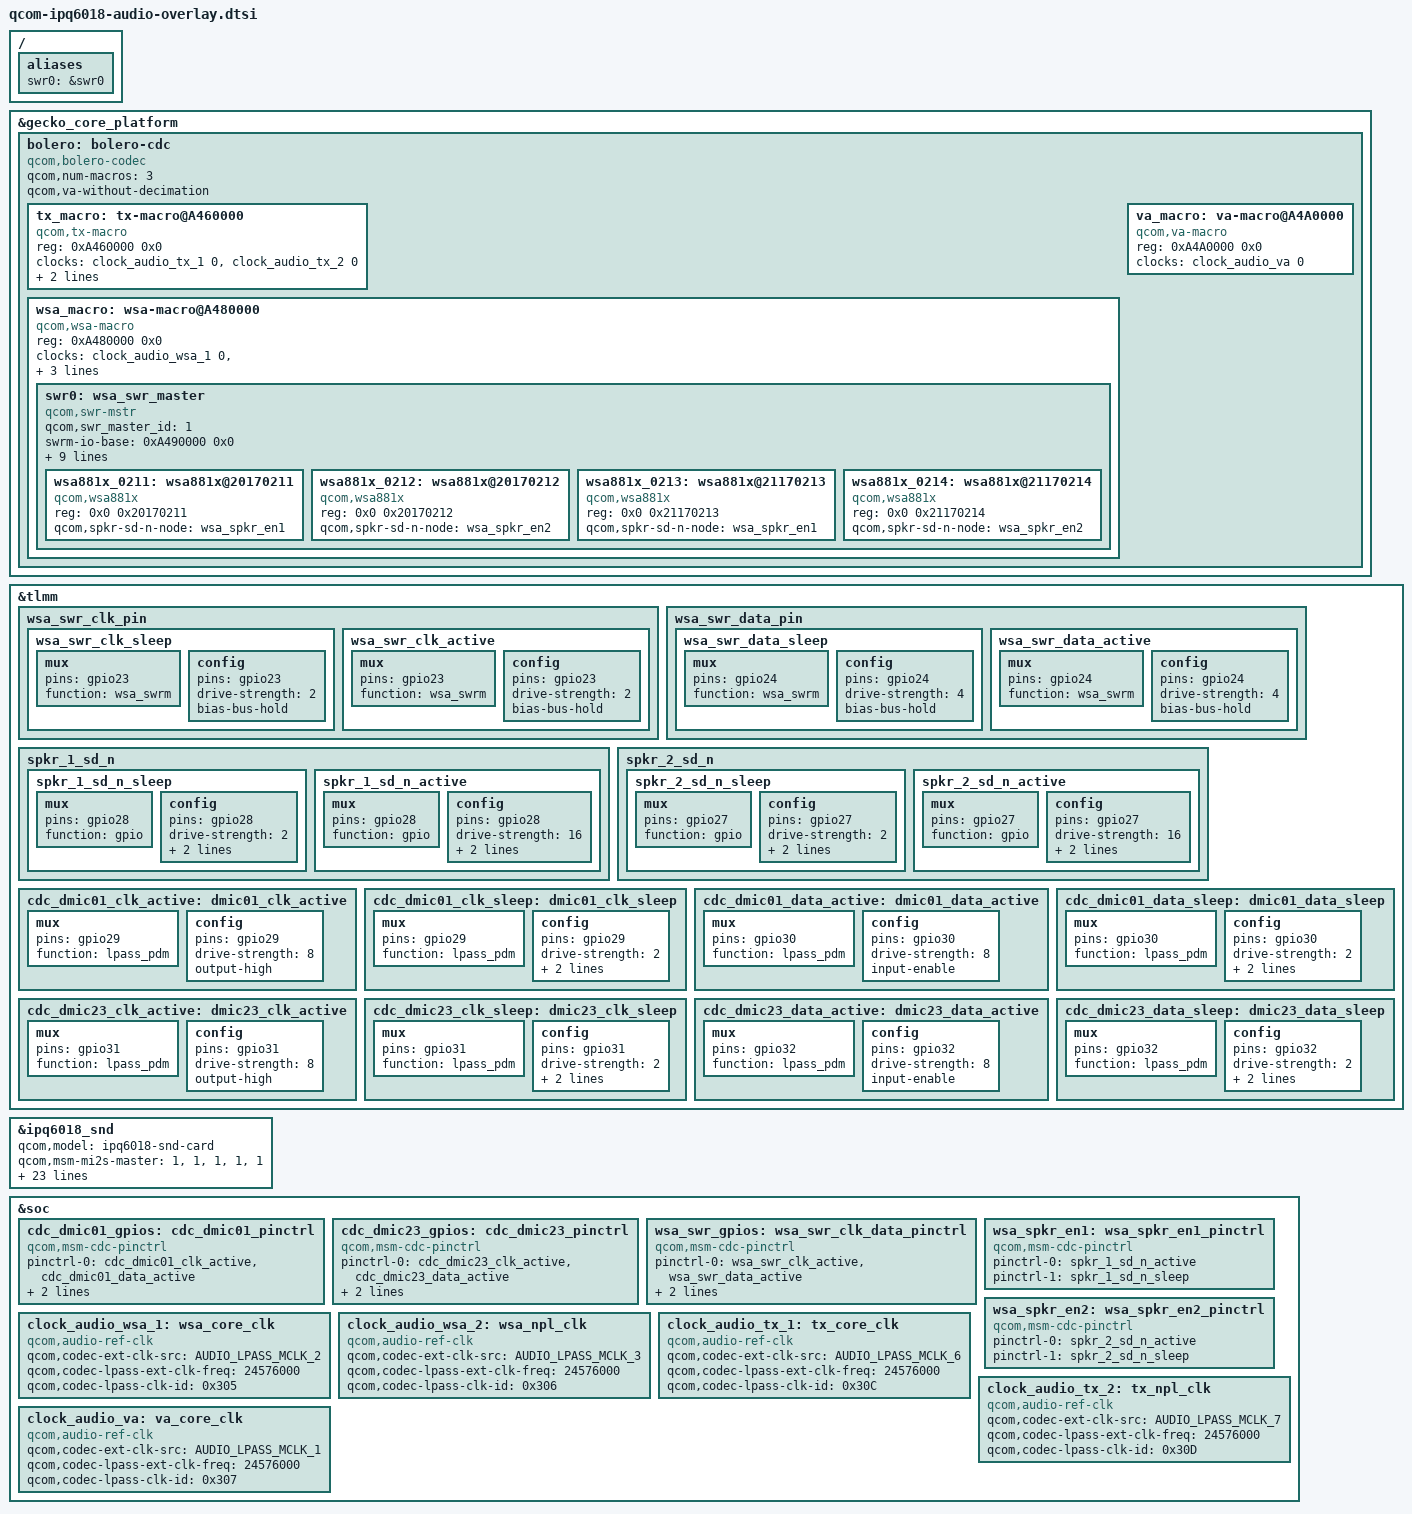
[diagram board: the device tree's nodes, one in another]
/*
 * Copyright (c) 2019, The Linux Foundation. All rights reserved.
 *
 * This program is free software; you can redistribute it and/or modify
 * it under the terms of the GNU General Public License version 2 and
 * only version 2 as published by the Free Software Foundation.
 *
 * This program is distributed in the hope that it will be useful,
 * but WITHOUT ANY WARRANTY; without even the implied warranty of
 * MERCHANTABILITY or FITNESS FOR A PARTICULAR PURPOSE.  See the
 * GNU General Public License for more details.
 */

#include <dt-bindings/clock/qcom,audio-ext-clk.h>
#include <dt-bindings/sound/audio-codec-port-types.h>
#include "qcom-ipq6018-audio.dtsi"

/ {
	aliases {
		swr0 = &swr0;
	};
};

&gecko_core_platform {
	bolero: bolero-cdc {
		compatible = "qcom,bolero-codec";
		tx_macro: tx-macro@A460000 {
		};

		wsa_macro: wsa-macro@A480000 {
			swr0: wsa_swr_master {
			};
		};
	};
};

&bolero {
	qcom,num-macros = <3>;
	qcom,va-without-decimation;
	#address-cells = <1>;
	#size-cells = <1>;
	tx_macro: tx-macro@A460000 {
		compatible = "qcom,tx-macro";
		reg = <0xA460000 0x0>;
		clock-names = "tx_core_clk", "tx_npl_clk";
		clocks = <&clock_audio_tx_1 0>,
			 <&clock_audio_tx_2 0>;
		qcom,tx-dmic-sample-rate = <3072000>;
		qcom,tx-mclk-freq = <12288000>;
	};

	wsa_macro: wsa-macro@A480000 {
		compatible = "qcom,wsa-macro";
		reg = <0xA480000 0x0>;
		clock-names = "wsa_core_clk", "wsa_npl_clk";
		clocks = <&clock_audio_wsa_1 0>,
			 <&clock_audio_wsa_2 0>;
		qcom,wsa-mclk-freq = <12288000>;
		qcom,wsa-swr-gpios = <&wsa_swr_gpios>;
		swr0: wsa_swr_master {
			compatible = "qcom,swr-mstr";
			#address-cells = <2>;
			#size-cells = <0>;
			qcom,swr_master_id = <1>;
			swrm-io-base = <0xA490000 0x0>;
			interrupts = <0 141 0>;
			interrupt-names = "swr_master_irq";
			qcom,swr-num-ports = <8>;
			qcom,swr-port-mapping = <1 SPKR_L 0x1>,
				<2 SPKR_L_COMP 0xF>, <3 SPKR_L_BOOST 0x3>,
				<4 SPKR_R 0x1>, <5 SPKR_R_COMP 0xF>,
				<6 SPKR_R_BOOST 0x3>, <7 SPKR_L_VI 0x3>,
				<8 SPKR_R_VI 0x3>;
			qcom,swr-num-dev = <2>;
			qcom,swr-mclk-freq = <12288000>;
			wsa881x_0211: wsa881x@20170211 {
				compatible = "qcom,wsa881x";
				reg = <0x0 0x20170211>;
				qcom,spkr-sd-n-node = <&wsa_spkr_en1>;
			};

			wsa881x_0212: wsa881x@20170212 {
				compatible = "qcom,wsa881x";
				reg = <0x0 0x20170212>;
				qcom,spkr-sd-n-node = <&wsa_spkr_en2>;
			};

			wsa881x_0213: wsa881x@21170213 {
				compatible = "qcom,wsa881x";
				reg = <0x0 0x21170213>;
				qcom,spkr-sd-n-node = <&wsa_spkr_en1>;
			};

			wsa881x_0214: wsa881x@21170214 {
				compatible = "qcom,wsa881x";
				reg = <0x0 0x21170214>;
				qcom,spkr-sd-n-node = <&wsa_spkr_en2>;
			};
		};

	};

	va_macro: va-macro@A4A0000 {
		compatible = "qcom,va-macro";
		reg = <0xA4A0000 0x0>;
		clock-names = "va_core_clk";
		clocks = <&clock_audio_va 0>;
	};

};

&tlmm {
	wsa_swr_clk_pin {
		wsa_swr_clk_sleep: wsa_swr_clk_sleep {
			mux {
				pins = "gpio23";
				function = "wsa_swrm";
			};

			config {
				pins = "gpio23";
				drive-strength = <2>;
				bias-bus-hold;
			};
		};

		wsa_swr_clk_active: wsa_swr_clk_active {
			mux {
				pins = "gpio23";
				function = "wsa_swrm";
			};

			config {
				pins = "gpio23";
				drive-strength = <2>;
				bias-bus-hold;
			};
		};
	};

	wsa_swr_data_pin {
		wsa_swr_data_sleep: wsa_swr_data_sleep {
			mux {
				pins = "gpio24";
				function = "wsa_swrm";
			};

			config {
				pins = "gpio24";
				drive-strength = <4>;
				bias-bus-hold;
			};
		};

		wsa_swr_data_active: wsa_swr_data_active {
			mux {
				pins = "gpio24";
				function = "wsa_swrm";
			};

			config {
				pins = "gpio24";
				drive-strength = <4>;
				bias-bus-hold;
			};
		};
	};

	/* WSA speaker reset pins */
	spkr_1_sd_n {
		spkr_1_sd_n_sleep: spkr_1_sd_n_sleep {
			mux {
				pins = "gpio28";
				function = "gpio";
			};

			config {
				pins = "gpio28";
				drive-strength = <2>;
				bias-pull-down;
				input-enable;
			};
		};

		spkr_1_sd_n_active: spkr_1_sd_n_active {
			mux {
				pins = "gpio28";
				function = "gpio";
			};

			config {
				pins = "gpio28";
				drive-strength = <16>;
				bias-disable;
				output-high;
			};
		};
	};

	spkr_2_sd_n {
		spkr_2_sd_n_sleep: spkr_2_sd_n_sleep {
			mux {
				pins = "gpio27";
				function = "gpio";
			};

			config {
				pins = "gpio27";
				drive-strength = <2>;
				bias-pull-down;
				input-enable;
			};
		};

		spkr_2_sd_n_active: spkr_2_sd_n_active {
			mux {
				pins = "gpio27";
				function = "gpio";
			};

			config {
				pins = "gpio27";
				drive-strength = <16>;
				bias-disable;
				output-high;
			};
		};
	};

	cdc_dmic01_clk_active: dmic01_clk_active {
		mux {
			pins = "gpio29";
			function = "lpass_pdm";
		};

		config {
			pins = "gpio29";
			drive-strength = <8>;
			output-high;
		};
	};

	cdc_dmic01_clk_sleep: dmic01_clk_sleep {
		mux {
			pins = "gpio29";
			function = "lpass_pdm";
		};

		config {
			pins = "gpio29";
			drive-strength = <2>;
			bias-disable;
			output-low;
		};
	};

	cdc_dmic01_data_active: dmic01_data_active {
		mux {
			pins = "gpio30";
			function = "lpass_pdm";
		};

		config {
			pins = "gpio30";
			drive-strength = <8>;
			input-enable;
		};
	};

	cdc_dmic01_data_sleep: dmic01_data_sleep {
		mux {
			pins = "gpio30";
			function = "lpass_pdm";
		};

		config {
			pins = "gpio30";
			drive-strength = <2>;
			pull-down;
			input-enable;
		};
	};

	cdc_dmic23_clk_active: dmic23_clk_active {
		mux {
			pins = "gpio31";
			function = "lpass_pdm";
		};

		config {
			pins = "gpio31";
			drive-strength = <8>;
			output-high;
		};
	};

	cdc_dmic23_clk_sleep: dmic23_clk_sleep {
		mux {
			pins = "gpio31";
			function = "lpass_pdm";
		};

		config {
			pins = "gpio31";
			drive-strength = <2>;
			bias-disable;
			output-low;
		};
	};

	cdc_dmic23_data_active: dmic23_data_active {
		mux {
			pins = "gpio32";
			function = "lpass_pdm";
		};

		config {
			pins = "gpio32";
			drive-strength = <8>;
			input-enable;
		};
	};

	cdc_dmic23_data_sleep: dmic23_data_sleep {
		mux {
			pins = "gpio32";
			function = "lpass_pdm";
		};

		config {
			pins = "gpio32";
			drive-strength = <2>;
			pull-down;
			input-enable;
		};
	};
};

&ipq6018_snd {
	qcom,model = "ipq6018-snd-card";
	qcom,msm-mi2s-master = <1>, <1>, <1>, <1>, <1>;
	qcom,audio-routing =
		"TX_AIF1 CAP", "VA_MCLK",
		"TX DMIC0", "TX MIC BIAS1",
		"TX MIC BIAS1", "Digital Mic0",
		"TX DMIC1", "TX MIC BIAS1",
		"TX MIC BIAS1", "Digital Mic1",
		"TX DMIC2", "TX MIC BIAS1",
		"TX MIC BIAS1", "Digital Mic2",
		"TX DMIC3", "TX MIC BIAS1",
		"TX MIC BIAS1", "Digital Mic3",
		"TX_AIF2 CAP", "VA_MCLK",
		"WSA_TX DEC0_INP", "TX DEC0 MUX",
		"WSA_TX DEC1_INP", "TX DEC1 MUX",
		"SpkrLeft IN", "WSA_SPK1 OUT",
		"SpkrRight IN", "WSA_SPK2 OUT",
		"WSA_SPK1 OUT", "VA_MCLK",
		"WSA_SPK2 OUT", "VA_MCLK";
	qcom,cdc-dmic01-gpios = <&cdc_dmic01_gpios>;
	qcom,cdc-dmic23-gpios = <&cdc_dmic23_gpios>;
	asoc-codec  = <&stub_codec>, <&bolero>;
	asoc-codec-names = "msm-stub-codec.1", "bolero_codec";
	qcom,wsa-max-devs = <2>;
	qcom,wsa-devs = <&wsa881x_0211>, <&wsa881x_0212>,
			<&wsa881x_0213>, <&wsa881x_0214>;
	qcom,wsa-aux-dev-prefix = "SpkrLeft", "SpkrRight",
				  "SpkrLeft", "SpkrRight";
	qcom,msm_audio_ssr_devs = <&gecko_core_platform>,
					<&bolero>;
};

&soc {
	cdc_dmic01_gpios: cdc_dmic01_pinctrl {
		compatible = "qcom,msm-cdc-pinctrl";
		pinctrl-names = "aud_active", "aud_sleep";
		pinctrl-0 = <&cdc_dmic01_clk_active &cdc_dmic01_data_active>;
		pinctrl-1 = <&cdc_dmic01_clk_sleep &cdc_dmic01_data_sleep>;
	};

	cdc_dmic23_gpios: cdc_dmic23_pinctrl {
		compatible = "qcom,msm-cdc-pinctrl";
		pinctrl-names = "aud_active", "aud_sleep";
		pinctrl-0 = <&cdc_dmic23_clk_active &cdc_dmic23_data_active>;
		pinctrl-1 = <&cdc_dmic23_clk_sleep &cdc_dmic23_data_sleep>;
	};

	wsa_swr_gpios: wsa_swr_clk_data_pinctrl {
		compatible = "qcom,msm-cdc-pinctrl";
		pinctrl-names = "aud_active", "aud_sleep";
		pinctrl-0 = <&wsa_swr_clk_active &wsa_swr_data_active>;
		pinctrl-1 = <&wsa_swr_clk_sleep &wsa_swr_data_sleep>;
	};

	wsa_spkr_en1: wsa_spkr_en1_pinctrl {
		compatible = "qcom,msm-cdc-pinctrl";
		pinctrl-names = "aud_active", "aud_sleep";
		pinctrl-0 = <&spkr_1_sd_n_active>;
		pinctrl-1 = <&spkr_1_sd_n_sleep>;
	};

	wsa_spkr_en2: wsa_spkr_en2_pinctrl {
		compatible = "qcom,msm-cdc-pinctrl";
		pinctrl-names = "aud_active", "aud_sleep";
		pinctrl-0 = <&spkr_2_sd_n_active>;
		pinctrl-1 = <&spkr_2_sd_n_sleep>;
	};

	clock_audio_wsa_1: wsa_core_clk {
		compatible = "qcom,audio-ref-clk";
		qcom,codec-ext-clk-src = <AUDIO_LPASS_MCLK_2>;
		qcom,codec-lpass-ext-clk-freq = <24576000>;
		qcom,codec-lpass-clk-id = <0x305>;
		#clock-cells = <1>;
	};

	clock_audio_wsa_2: wsa_npl_clk {
		compatible = "qcom,audio-ref-clk";
		qcom,codec-ext-clk-src = <AUDIO_LPASS_MCLK_3>;
		qcom,codec-lpass-ext-clk-freq = <24576000>;
		qcom,codec-lpass-clk-id = <0x306>;
		#clock-cells = <1>;
	};

	clock_audio_tx_1: tx_core_clk {
		compatible = "qcom,audio-ref-clk";
		qcom,codec-ext-clk-src = <AUDIO_LPASS_MCLK_6>;
		qcom,codec-lpass-ext-clk-freq = <24576000>;
		qcom,codec-lpass-clk-id = <0x30C>;
		#clock-cells = <1>;
	};

	clock_audio_tx_2: tx_npl_clk {
		compatible = "qcom,audio-ref-clk";
		qcom,codec-ext-clk-src = <AUDIO_LPASS_MCLK_7>;
		qcom,codec-lpass-ext-clk-freq = <24576000>;
		qcom,codec-lpass-clk-id = <0x30D>;
		#clock-cells = <1>;
	};
	clock_audio_va: va_core_clk {
		compatible = "qcom,audio-ref-clk";
		qcom,codec-ext-clk-src = <AUDIO_LPASS_MCLK_1>;
		qcom,codec-lpass-ext-clk-freq = <24576000>;
		qcom,codec-lpass-clk-id = <0x307>;
		#clock-cells = <1>;
	};

};
